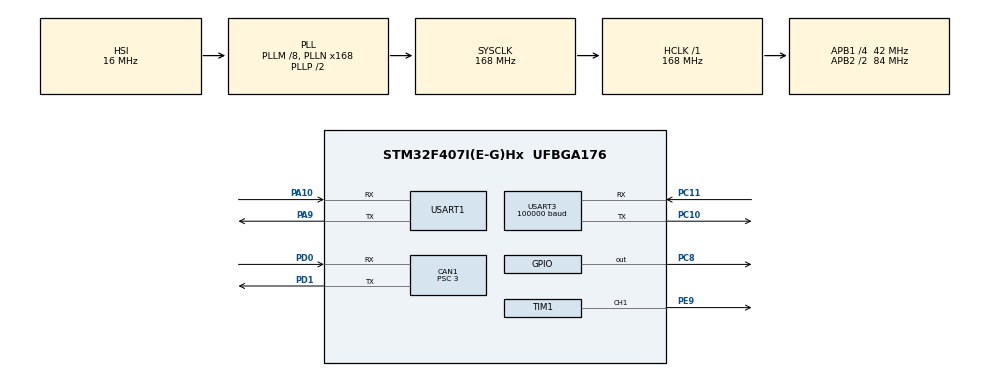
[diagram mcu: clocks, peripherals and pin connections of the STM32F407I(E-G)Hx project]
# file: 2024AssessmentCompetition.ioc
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CAN1.BS1=CAN_BS1_10TQ
CAN1.BS2=CAN_BS2_3TQ
CAN1.CalculateBaudRate=1000000
CAN1.CalculateTimeBit=1000
CAN1.CalculateTimeQuantum=71.42857142857143
CAN1.Prescaler=3
Dma.Request0=USART3_RX
Dma.USART3_RX.0.Direction=DMA_PERIPH_TO_MEMORY
Dma.USART3_RX.0.FIFOMode=DMA_FIFOMODE_DISABLE
Dma.USART3_RX.0.Instance=DMA1_Stream1
Dma.USART3_RX.0.MemDataAlignment=DMA_MDATAALIGN_BYTE
Dma.USART3_RX.0.MemInc=DMA_MINC_ENABLE
Dma.USART3_RX.0.Mode=DMA_NORMAL
Dma.USART3_RX.0.PeriphDataAlignment=DMA_PDATAALIGN_BYTE
Dma.USART3_RX.0.PeriphInc=DMA_PINC_DISABLE
Dma.USART3_RX.0.Priority=DMA_PRIORITY_VERY_HIGH
FREERTOS.Tasks01=defaultTask,-3,128,StartDefaultTask,Default,NULL,Dynamic,NULL,NULL;ChassisTask,0,128,chassis_task,As weak,NULL,Dynamic,NULL,NULL;GimbalTask,0,128,gimbal_task,As weak,NULL,Dynamic,NULL,NULL;ServoTask,0,128,servo_task,As weak,NULL,Dynamic,NULL,NULL;LaserTask,0,128,laser_task,As weak,NULL,Dynamic,NULL,NULL
Mcu.Family=STM32F4
Mcu.Name=STM32F407I(E-G)Hx
Mcu.Package=UFBGA176
NVIC.CAN1_RX0_IRQn=true\:6\:0\:true\:false\:true\:true\:true\:true\:true
NVIC.DMA1_Stream1_IRQn=true\:5\:0\:false\:false\:true\:true\:false\:true\:true
NVIC.PriorityGroup=NVIC_PRIORITYGROUP_4
NVIC.USART1_IRQn=true\:5\:0\:false\:false\:true\:true\:true\:true\:true
NVIC.USART3_IRQn=true\:4\:0\:true\:false\:false\:false\:true\:true\:true
PA10.Mode=Asynchronous
PA10.Signal=USART1_RX
PA9.Mode=Asynchronous
PA9.Signal=USART1_TX
PC10.Mode=Asynchronous
PC10.Signal=USART3_TX
PC11.Mode=Asynchronous
PC11.Signal=USART3_RX
PC14-OSC32_IN.Mode=LSE-External-Oscillator
PC14-OSC32_IN.Signal=RCC_OSC32_IN
PC15-OSC32_OUT.Mode=LSE-External-Oscillator
PC15-OSC32_OUT.Signal=RCC_OSC32_OUT
PC8.PinState=GPIO_PIN_SET
PC8.Signal=GPIO_Output
PD0.Mode=CAN_Activate
PD0.Signal=CAN1_RX
PD1.Mode=CAN_Activate
PD1.Signal=CAN1_TX
PE9.Signal=S_TIM1_CH1
PH0-OSC_IN.Mode=HSE-External-Oscillator
PH0-OSC_IN.Signal=RCC_OSC_IN
PH1-OSC_OUT.Mode=HSE-External-Oscillator
PH1-OSC_OUT.Signal=RCC_OSC_OUT
ProjectManager.HeapSize=0x200
ProjectManager.StackSize=0x400
ProjectManager.TargetToolchain=MDK-ARM V5.32
RCC.48MHZClocksFreq_Value=84000000
RCC.AHBFreq_Value=168000000
RCC.APB1CLKDivider=RCC_HCLK_DIV4
RCC.APB1Freq_Value=42000000
RCC.APB1TimFreq_Value=84000000
RCC.APB2CLKDivider=RCC_HCLK_DIV2
RCC.APB2Freq_Value=84000000
RCC.APB2TimFreq_Value=168000000
RCC.CortexFreq_Value=168000000
RCC.HCLKFreq_Value=168000000
RCC.HSE_VALUE=25000000
RCC.HSI_VALUE=16000000
RCC.PLLM=8
RCC.PLLN=168
RCC.SYSCLKFreq_VALUE=168000000
RCC.SYSCLKSource=RCC_SYSCLKSOURCE_PLLCLK
RCC.VCOOutputFreq_Value=336000000
SH.S_TIM1_CH1.0=TIM1_CH1,PWM Generation1 CH1
TIM1.Channel-PWM\ Generation1\ CH1=TIM_CHANNEL_1
TIM1.Period=1000-1
TIM1.Prescaler=3360-1
USART1.VirtualMode=VM_ASYNC
USART3.BaudRate=100000
USART3.Parity=PARITY_EVEN
USART3.VirtualMode=VM_ASYNC
USART3.WordLength=WORDLENGTH_8B
VP_FREERTOS_VS_CMSIS_V1.Mode=CMSIS_V1
board=custom

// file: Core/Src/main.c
/* USER CODE BEGIN Header */
/**
  ******************************************************************************
  * @file           : main.c
  * @brief          : Main program body
  ******************************************************************************
  * @attention
  *
  * Copyright (c) 2023 STMicroelectronics.
  * All rights reserved.
  *
  * This software is licensed under terms that can be found in the LICENSE file
  * in the root directory of this software component.
  * If no LICENSE file comes with this software, it is provided AS-IS.
  *
  ******************************************************************************
  */
/* USER CODE END Header */
#include "main.h"
#include "cmsis_os.h"
#include "can.h"
#include "dma.h"
#include "tim.h"
#include "usart.h"
#include "gpio.h"

/* USER CODE BEGIN Includes */
#include "RemoteTask.h"
/* USER CODE END Includes */

void SystemClock_Config(void);
void MX_FREERTOS_Init(void);

int main(void)
{

  /* MCU Configuration--------------------------------------------------------*/

  /* Reset of all peripherals, Initializes the Flash interface and the Systick. */
  HAL_Init();

  /* Configure the system clock */
  SystemClock_Config();

  /* Initialize all configured peripherals */
  MX_GPIO_Init();
  MX_DMA_Init();
  MX_CAN1_Init();
  MX_USART3_UART_Init();
  MX_USART1_UART_Init();
  MX_TIM1_Init();
  /* USER CODE BEGIN 2 */
  can_filter_init();
  remote_control_init();
  HAL_TIM_PWM_Start(&htim1,TIM_CHANNEL_1);
  /* USER CODE END 2 */

  /* Call init function for freertos objects (in freertos.c) */
  MX_FREERTOS_Init();

  /* Start scheduler */
  osKernelStart();

  /* We should never get here as control is now taken by the scheduler */
  /* Infinite loop */
  while (1)
  {

  }
}

void SystemClock_Config(void)
{
  RCC_OscInitTypeDef RCC_OscInitStruct = {0};
  RCC_ClkInitTypeDef RCC_ClkInitStruct = {0};

  /** Configure the main internal regulator output voltage
  */
  __HAL_RCC_PWR_CLK_ENABLE();
  __HAL_PWR_VOLTAGESCALING_CONFIG(PWR_REGULATOR_VOLTAGE_SCALE1);

  /** Initializes the RCC Oscillators according to the specified parameters
  * in the RCC_OscInitTypeDef structure.
  */
  RCC_OscInitStruct.OscillatorType = RCC_OSCILLATORTYPE_HSI;
  RCC_OscInitStruct.HSIState = RCC_HSI_ON;
  RCC_OscInitStruct.HSICalibrationValue = RCC_HSICALIBRATION_DEFAULT;
  RCC_OscInitStruct.PLL.PLLState = RCC_PLL_ON;
  RCC_OscInitStruct.PLL.PLLSource = RCC_PLLSOURCE_HSI;
  RCC_OscInitStruct.PLL.PLLM = 8;
  RCC_OscInitStruct.PLL.PLLN = 168;
  RCC_OscInitStruct.PLL.PLLP = RCC_PLLP_DIV2;
  RCC_OscInitStruct.PLL.PLLQ = 4;
  if (HAL_RCC_OscConfig(&RCC_OscInitStruct) != HAL_OK)
  {
    Error_Handler();
  }

  /** Initializes the CPU, AHB and APB buses clocks
  */
  RCC_ClkInitStruct.ClockType = RCC_CLOCKTYPE_HCLK|RCC_CLOCKTYPE_SYSCLK
                              |RCC_CLOCKTYPE_PCLK1|RCC_CLOCKTYPE_PCLK2;
  RCC_ClkInitStruct.SYSCLKSource = RCC_SYSCLKSOURCE_PLLCLK;
  RCC_ClkInitStruct.AHBCLKDivider = RCC_SYSCLK_DIV1;
  RCC_ClkInitStruct.APB1CLKDivider = RCC_HCLK_DIV4;
  RCC_ClkInitStruct.APB2CLKDivider = RCC_HCLK_DIV2;

  if (HAL_RCC_ClockConfig(&RCC_ClkInitStruct, FLASH_LATENCY_5) != HAL_OK)
  {
    Error_Handler();
  }
}

void Error_Handler(void)
{
  __disable_irq();
  while (1)
  {
  }
}

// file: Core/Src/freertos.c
/* USER CODE BEGIN Header */
/**
  ******************************************************************************
  * File Name          : freertos.c
  * Description        : Code for freertos applications
  ******************************************************************************
  * @attention
  *
  * Copyright (c) 2023 STMicroelectronics.
  * All rights reserved.
  *
  * This software is licensed under terms that can be found in the LICENSE file
  * in the root directory of this software component.
  * If no LICENSE file comes with this software, it is provided AS-IS.
  *
  ******************************************************************************
  */
/* USER CODE END Header */

#include "FreeRTOS.h"
#include "task.h"
#include "main.h"
#include "cmsis_os.h"

osThreadId defaultTaskHandle;
osThreadId ChassisTaskHandle;
osThreadId GimbalTaskHandle;
osThreadId ServoTaskHandle;
osThreadId LaserTaskHandle;

void StartDefaultTask(void const * argument);
void chassis_task(void const * argument);
void gimbal_task(void const * argument);
void servo_task(void const * argument);
void laser_task(void const * argument);

void MX_FREERTOS_Init(void); /* (MISRA C 2004 rule 8.1) */

/* GetIdleTaskMemory prototype (linked to static allocation support) */
void vApplicationGetIdleTaskMemory( StaticTask_t **ppxIdleTaskTCBBuffer, StackType_t **ppxIdleTaskStackBuffer, uint32_t *pulIdleTaskStackSize );

/* USER CODE BEGIN GET_IDLE_TASK_MEMORY */
static StaticTask_t xIdleTaskTCBBuffer;
static StackType_t xIdleStack[configMINIMAL_STACK_SIZE];

void vApplicationGetIdleTaskMemory( StaticTask_t **ppxIdleTaskTCBBuffer, StackType_t **ppxIdleTaskStackBuffer, uint32_t *pulIdleTaskStackSize )
{
  *ppxIdleTaskTCBBuffer = &xIdleTaskTCBBuffer;
  *ppxIdleTaskStackBuffer = &xIdleStack[0];
  *pulIdleTaskStackSize = configMINIMAL_STACK_SIZE;
  /* place for user code */
}
/* USER CODE END GET_IDLE_TASK_MEMORY */

void MX_FREERTOS_Init(void) {

  /* Create the thread(s) */
  /* definition and creation of defaultTask */
  osThreadDef(defaultTask, StartDefaultTask, osPriorityIdle, 0, 128);
  defaultTaskHandle = osThreadCreate(osThread(defaultTask), NULL);

  /* definition and creation of ChassisTask */
  osThreadDef(ChassisTask, chassis_task, osPriorityNormal, 0, 512);
  ChassisTaskHandle = osThreadCreate(osThread(ChassisTask), NULL);

  /* definition and creation of GimbalTask */
  osThreadDef(GimbalTask, gimbal_task, osPriorityNormal, 0, 512);
  GimbalTaskHandle = osThreadCreate(osThread(GimbalTask), NULL);

  /* definition and creation of ServoTask */
  osThreadDef(ServoTask, servo_task, osPriorityNormal, 0, 256);
  ServoTaskHandle = osThreadCreate(osThread(ServoTask), NULL);

  /* definition and creation of LaserTask */
  osThreadDef(LaserTask, laser_task, osPriorityNormal, 0, 256);
  LaserTaskHandle = osThreadCreate(osThread(LaserTask), NULL);

}

void StartDefaultTask(void const * argument)
{
  for(;;)
  {
    osDelay(1);
  }
}

__weak void chassis_task(void const * argument)
{
  for(;;)
  {
    osDelay(1);
  }
}

__weak void gimbal_task(void const * argument)
{
  for(;;)
  {
    osDelay(1);
  }
}

__weak void servo_task(void const * argument)
{
  for(;;)
  {
    osDelay(1);
  }
}

__weak void laser_task(void const * argument)
{
  for(;;)
  {
    osDelay(1);
  }
}
